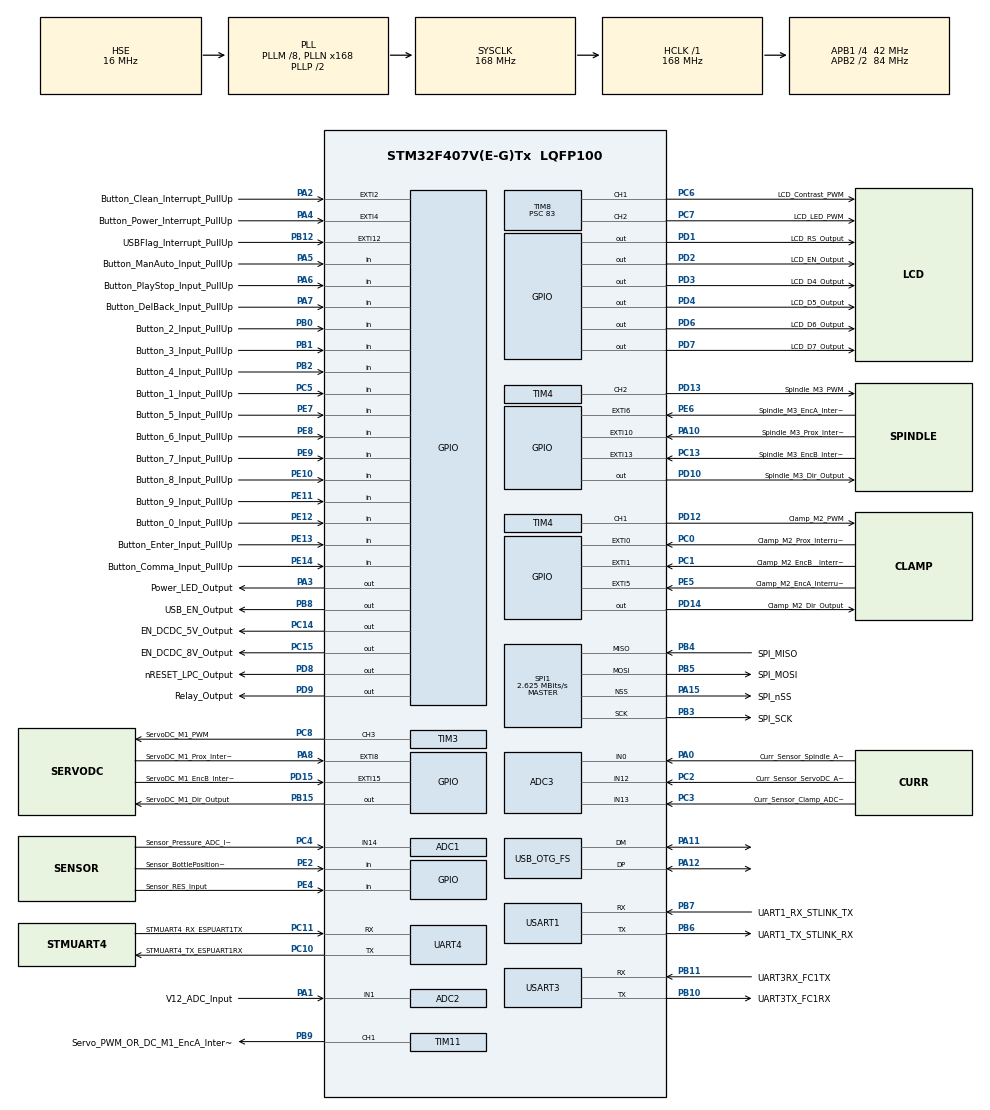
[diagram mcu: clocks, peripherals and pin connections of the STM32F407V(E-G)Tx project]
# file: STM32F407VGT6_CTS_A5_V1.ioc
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ADC1.Channel-0\#ChannelRegularConversion=ADC_CHANNEL_14
ADC1.ClockPrescaler=ADC_CLOCK_SYNC_PCLK_DIV8
ADC1.NbrOfConversionFlag=1
ADC1.Rank-0\#ChannelRegularConversion=1
ADC1.SamplingTime-0\#ChannelRegularConversion=ADC_SAMPLETIME_3CYCLES
ADC1.master=1
ADC2.Channel-0\#ChannelRegularConversion=ADC_CHANNEL_1
ADC2.ClockPrescaler=ADC_CLOCK_SYNC_PCLK_DIV8
ADC2.NbrOfConversionFlag=1
ADC2.Rank-0\#ChannelRegularConversion=1
ADC2.SamplingTime-0\#ChannelRegularConversion=ADC_SAMPLETIME_3CYCLES
ADC3.Channel-0\#ChannelRegularConversion=ADC_CHANNEL_0
ADC3.ClockPrescaler=ADC_CLOCK_SYNC_PCLK_DIV8
ADC3.ContinuousConvMode=ENABLE
ADC3.NbrOfConversion=1
ADC3.NbrOfConversionFlag=1
ADC3.Rank-0\#ChannelRegularConversion=1
ADC3.SamplingTime-0\#ChannelRegularConversion=ADC_SAMPLETIME_3CYCLES
Dma.Request0=USART3_RX
Dma.Request1=USART3_TX
Dma.Request2=USART1_RX
Dma.USART1_RX.2.Direction=DMA_PERIPH_TO_MEMORY
Dma.USART1_RX.2.FIFOMode=DMA_FIFOMODE_DISABLE
Dma.USART1_RX.2.Instance=DMA2_Stream2
Dma.USART1_RX.2.MemDataAlignment=DMA_MDATAALIGN_BYTE
Dma.USART1_RX.2.MemInc=DMA_MINC_ENABLE
Dma.USART1_RX.2.Mode=DMA_NORMAL
Dma.USART1_RX.2.PeriphDataAlignment=DMA_PDATAALIGN_BYTE
Dma.USART1_RX.2.PeriphInc=DMA_PINC_DISABLE
Dma.USART1_RX.2.Priority=DMA_PRIORITY_LOW
Dma.USART3_RX.0.Direction=DMA_PERIPH_TO_MEMORY
Dma.USART3_RX.0.FIFOMode=DMA_FIFOMODE_DISABLE
Dma.USART3_RX.0.Instance=DMA1_Stream1
Dma.USART3_RX.0.MemDataAlignment=DMA_MDATAALIGN_BYTE
Dma.USART3_RX.0.MemInc=DMA_MINC_ENABLE
Dma.USART3_RX.0.Mode=DMA_NORMAL
Dma.USART3_RX.0.PeriphDataAlignment=DMA_PDATAALIGN_BYTE
Dma.USART3_RX.0.PeriphInc=DMA_PINC_DISABLE
Dma.USART3_RX.0.Priority=DMA_PRIORITY_LOW
Dma.USART3_TX.1.Direction=DMA_MEMORY_TO_PERIPH
Dma.USART3_TX.1.FIFOMode=DMA_FIFOMODE_DISABLE
Dma.USART3_TX.1.Instance=DMA1_Stream3
Dma.USART3_TX.1.MemDataAlignment=DMA_MDATAALIGN_BYTE
Dma.USART3_TX.1.MemInc=DMA_MINC_ENABLE
Dma.USART3_TX.1.Mode=DMA_NORMAL
Dma.USART3_TX.1.PeriphDataAlignment=DMA_PDATAALIGN_BYTE
Dma.USART3_TX.1.PeriphInc=DMA_PINC_DISABLE
Dma.USART3_TX.1.Priority=DMA_PRIORITY_LOW
FATFS._MAX_SS=4096
FATFS._USE_LFN=1
FREERTOS.Tasks01=defaultTask,0,128,StartDefaultTask,Default,NULL,Dynamic,NULL,NULL
Mcu.Family=STM32F4
Mcu.Name=STM32F407V(E-G)Tx
Mcu.Package=LQFP100
NVIC.DMA1_Stream1_IRQn=true\:5\:0\:false\:false\:true\:true\:false\:true\:true
NVIC.DMA1_Stream3_IRQn=true\:5\:0\:false\:false\:true\:true\:false\:true\:true
NVIC.DMA2_Stream2_IRQn=true\:5\:0\:false\:false\:true\:true\:false\:true\:true
NVIC.EXTI0_IRQn=true\:5\:0\:false\:true\:true\:8\:true\:true\:true\:true
NVIC.EXTI15_10_IRQn=true\:5\:0\:false\:true\:true\:2\:true\:true\:true\:true
NVIC.EXTI1_IRQn=true\:5\:0\:false\:true\:true\:7\:true\:true\:true\:true
NVIC.EXTI2_IRQn=true\:5\:0\:false\:true\:true\:6\:true\:true\:true\:true
NVIC.EXTI4_IRQn=true\:5\:0\:false\:true\:true\:5\:true\:true\:true\:true
NVIC.EXTI9_5_IRQn=true\:5\:0\:false\:true\:true\:4\:true\:true\:true\:true
NVIC.FLASH_IRQn=true\:5\:0\:false\:false\:true\:true\:true\:true\:true
NVIC.PVD_IRQn=true\:5\:0\:false\:true\:true\:9\:true\:true\:true\:true
NVIC.PriorityGroup=NVIC_PRIORITYGROUP_4
NVIC.RCC_IRQn=true\:5\:0\:false\:false\:true\:true\:true\:false\:true
NVIC.TIM1_UP_TIM10_IRQn=true\:15\:0\:false\:false\:true\:false\:true\:true\:true
NVIC.TIM2_IRQn=true\:5\:0\:false\:true\:true\:3\:true\:true\:true\:true
NVIC.TIM6_DAC_IRQn=true\:5\:0\:false\:false\:true\:true\:true\:true\:true
NVIC.TIM7_IRQn=true\:5\:0\:false\:true\:true\:1\:true\:true\:true\:true
NVIC.TIM8_TRG_COM_TIM14_IRQn=true\:5\:0\:false\:false\:true\:true\:true\:true\:true
NVIC.TimeBase=TIM1_UP_TIM10_IRQn
NVIC.TimeBaseIP=TIM1
NVIC.USART1_IRQn=true\:5\:0\:false\:false\:true\:true\:true\:true\:true
NVIC.USART3_IRQn=true\:5\:0\:false\:false\:true\:true\:true\:true\:true
PA0-WKUP.GPIO_Label=Curr_Sensor_Spindle_ADC_Input
PA0-WKUP.Signal=ADCx_IN0
PA1.GPIO_Label=V12_ADC_Input
PA1.Signal=ADCx_IN1
PA10.GPIO_Label=Spindle_M3_Prox_Interrupt
PA10.GPIO_ModeDefaultEXTI=GPIO_MODE_IT_RISING_FALLING
PA10.GPIO_PuPd=GPIO_NOPULL
PA10.Signal=GPXTI10
PA11.Mode=Host_Only
PA11.Signal=USB_OTG_FS_DM
PA12.Mode=Host_Only
PA12.Signal=USB_OTG_FS_DP
PA13.Mode=Serial_Wire
PA13.Signal=SYS_JTMS-SWDIO
PA14.Mode=Serial_Wire
PA14.Signal=SYS_JTCK-SWCLK
PA15.GPIO_Label=SPI_nSS
PA15.Mode=NSS_Signal_Hard_Output
PA15.Signal=SPI1_NSS
PA2.GPIO_Label=Button_Clean_Interrupt_PullUp
PA2.GPIO_ModeDefaultEXTI=GPIO_MODE_IT_FALLING
PA2.GPIO_PuPd=GPIO_PULLUP
PA2.Signal=GPXTI2
PA3.GPIO_Label=Power_LED_Output
PA3.Signal=GPIO_Output
PA4.GPIO_Label=Button_Power_Interrupt_PullUp
PA4.GPIO_ModeDefaultEXTI=GPIO_MODE_IT_FALLING
PA4.GPIO_PuPd=GPIO_PULLUP
PA4.Signal=GPXTI4
PA5.GPIO_Label=Button_ManAuto_Input_PullUp
PA5.GPIO_PuPd=GPIO_PULLUP
PA5.Signal=GPIO_Input
PA6.GPIO_Label=Button_PlayStop_Input_PullUp
PA6.GPIO_PuPd=GPIO_PULLUP
PA6.Signal=GPIO_Input
PA7.GPIO_Label=Button_DelBack_Input_PullUp
PA7.GPIO_PuPd=GPIO_PULLUP
PA7.Signal=GPIO_Input
PA8.GPIO_Label=ServoDC_M1_Prox_Interrupt
PA8.GPIO_ModeDefaultEXTI=GPIO_MODE_IT_RISING_FALLING
PA8.GPIO_PuPd=GPIO_NOPULL
PA8.Signal=GPXTI8
PB0.GPIO_Label=Button_2_Input_PullUp
PB0.GPIO_PuPd=GPIO_PULLUP
PB0.Signal=GPIO_Input
PB1.GPIO_Label=Button_3_Input_PullUp
PB1.GPIO_PuPd=GPIO_PULLUP
PB1.Signal=GPIO_Input
PB10.GPIO_Label=UART3TX_FC1RX
PB10.Mode=Asynchronous
PB10.Signal=USART3_TX
PB11.GPIO_Label=UART3RX_FC1TX
PB11.Mode=Asynchronous
PB11.Signal=USART3_RX
PB12.GPIO_Label=USBFlag_Interrupt_PullUp
PB12.GPIO_ModeDefaultEXTI=GPIO_MODE_IT_FALLING
PB12.GPIO_PuPd=GPIO_PULLUP
PB12.Signal=GPXTI12
PB15.GPIO_Label=ServoDC_M1_Dir_Output
PB15.Signal=GPIO_Output
PB2.GPIO_Label=Button_4_Input_PullUp
PB2.GPIO_PuPd=GPIO_PULLUP
PB2.Signal=GPIO_Input
PB3.GPIO_Label=SPI_SCK
PB3.Mode=Full_Duplex_Master
PB3.Signal=SPI1_SCK
PB4.GPIO_Label=SPI_MISO
PB4.Mode=Full_Duplex_Master
PB4.Signal=SPI1_MISO
PB5.GPIO_Label=SPI_MOSI
PB5.Mode=Full_Duplex_Master
PB5.Signal=SPI1_MOSI
PB6.GPIO_Label=UART1_TX_STLINK_RX
PB6.Mode=Asynchronous
PB6.Signal=USART1_TX
PB7.GPIO_Label=UART1_RX_STLINK_TX
PB7.Mode=Asynchronous
PB7.Signal=USART1_RX
PB8.GPIO_Label=USB_EN_Output
PB8.Signal=GPIO_Output
PB9.GPIO_Label=Servo_PWM_OR_DC_M1_EncA_Interrupt
PB9.Signal=S_TIM11_CH1
PC0.GPIO_Label=Clamp_M2_Prox_Interrupt
PC0.GPIO_ModeDefaultEXTI=GPIO_MODE_IT_RISING_FALLING
PC0.GPIO_PuPd=GPIO_NOPULL
PC0.Signal=GPXTI0
PC1.GPIO_Label=Clamp_M2_EncB__Interrupt
PC1.GPIO_ModeDefaultEXTI=GPIO_MODE_IT_FALLING
PC1.GPIO_PuPd=GPIO_NOPULL
PC1.Signal=GPXTI1
PC10.GPIO_Label=STMUART4_TX_ESPUART1RX
PC10.Mode=Asynchronous
PC10.Signal=UART4_TX
PC11.GPIO_Label=STMUART4_RX_ESPUART1TX
PC11.Mode=Asynchronous
PC11.Signal=UART4_RX
PC13-ANTI_TAMP.GPIO_Label=Spindle_M3_EncB_Interrupt
PC13-ANTI_TAMP.GPIO_ModeDefaultEXTI=GPIO_MODE_IT_FALLING
PC13-ANTI_TAMP.GPIO_PuPd=GPIO_NOPULL
PC13-ANTI_TAMP.Signal=GPXTI13
PC14-OSC32_IN.GPIO_Label=EN_DCDC_5V_Output
PC14-OSC32_IN.Signal=GPIO_Output
PC15-OSC32_OUT.GPIO_Label=EN_DCDC_8V_Output
PC15-OSC32_OUT.Signal=GPIO_Output
PC2.GPIO_Label=Curr_Sensor_ServoDC_ADC_Input
PC2.Signal=ADCx_IN12
PC3.GPIO_Label=Curr_Sensor_Clamp_ADC_Input
PC3.Signal=ADCx_IN13
PC4.GPIO_Label=Sensor_Pressure_ADC_Input
PC4.Signal=ADCx_IN14
PC5.GPIO_Label=Button_1_Input_PullUp
PC5.GPIO_PuPd=GPIO_PULLUP
PC5.Signal=GPIO_Input
PC6.GPIO_Label=LCD_Contrast_PWM
PC6.Signal=S_TIM8_CH1
PC7.GPIO_Label=LCD_LED_PWM
PC7.Signal=S_TIM8_CH2
PC8.GPIO_Label=ServoDC_M1_PWM
PC8.Signal=S_TIM3_CH3
PD1.GPIO_Label=LCD_RS_Output
PD1.Signal=GPIO_Output
PD10.GPIO_Label=Spindle_M3_Dir_Output
PD10.Signal=GPIO_Output
PD12.GPIO_Label=Clamp_M2_PWM
PD12.Signal=S_TIM4_CH1
PD13.GPIO_Label=Spindle_M3_PWM
PD13.Signal=S_TIM4_CH2
PD14.GPIO_Label=Clamp_M2_Dir_Output
PD14.Signal=GPIO_Output
PD15.GPIO_Label=ServoDC_M1_EncB_Interrupt
PD15.GPIO_ModeDefaultEXTI=GPIO_MODE_IT_FALLING
PD15.GPIO_PuPd=GPIO_NOPULL
PD15.Signal=GPXTI15
PD2.GPIO_Label=LCD_EN_Output
PD2.Signal=GPIO_Output
PD3.GPIO_Label=LCD_D4_Output
PD3.Signal=GPIO_Output
PD4.GPIO_Label=LCD_D5_Output
PD4.Signal=GPIO_Output
PD6.GPIO_Label=LCD_D6_Output
PD6.Signal=GPIO_Output
PD7.GPIO_Label=LCD_D7_Output
PD7.Signal=GPIO_Output
PD8.GPIO_Label=nRESET_LPC_Output
PD8.Signal=GPIO_Output
PD9.GPIO_Label=Relay_Output
PD9.Signal=GPIO_Output
PE10.GPIO_Label=Button_8_Input_PullUp
PE10.GPIO_PuPd=GPIO_PULLUP
PE10.Signal=GPIO_Input
PE11.GPIO_Label=Button_9_Input_PullUp
PE11.GPIO_PuPd=GPIO_PULLUP
PE11.Signal=GPIO_Input
PE12.GPIO_Label=Button_0_Input_PullUp
PE12.GPIO_PuPd=GPIO_PULLUP
PE12.Signal=GPIO_Input
PE13.GPIO_Label=Button_Enter_Input_PullUp
PE13.GPIO_PuPd=GPIO_PULLUP
PE13.Signal=GPIO_Input
PE14.GPIO_Label=Button_Comma_Input_PullUp
PE14.GPIO_PuPd=GPIO_PULLUP
PE14.Signal=GPIO_Input
PE2.GPIO_Label=Sensor_BottlePosition_Input
PE2.Signal=GPIO_Input
PE4.GPIO_Label=Sensor_RES_Input
PE4.Signal=GPIO_Input
PE5.GPIO_Label=Clamp_M2_EncA_Interrupt
PE5.GPIO_ModeDefaultEXTI=GPIO_MODE_IT_FALLING
PE5.GPIO_PuPd=GPIO_NOPULL
PE5.Signal=GPXTI5
PE6.GPIO_Label=Spindle_M3_EncA_Interrupt
PE6.GPIO_ModeDefaultEXTI=GPIO_MODE_IT_FALLING
PE6.GPIO_PuPd=GPIO_NOPULL
PE6.Signal=GPXTI6
PE7.GPIO_Label=Button_5_Input_PullUp
PE7.GPIO_PuPd=GPIO_PULLUP
PE7.Signal=GPIO_Input
PE8.GPIO_Label=Button_6_Input_PullUp
PE8.GPIO_PuPd=GPIO_PULLUP
PE8.Signal=GPIO_Input
PE9.GPIO_Label=Button_7_Input_PullUp
PE9.GPIO_PuPd=GPIO_PULLUP
PE9.Signal=GPIO_Input
PH0-OSC_IN.GPIO_Label=PH0-OSC_IN
PH0-OSC_IN.Mode=HSE-External-Oscillator
PH0-OSC_IN.Signal=RCC_OSC_IN
PH1-OSC_OUT.GPIO_Label=PH1-OSC_OUT
PH1-OSC_OUT.Mode=HSE-External-Oscillator
PH1-OSC_OUT.Signal=RCC_OSC_OUT
ProjectManager.HeapSize=0x200
ProjectManager.StackSize=0x400
ProjectManager.TargetToolchain=STM32CubeIDE
RCC.48MHZClocksFreq_Value=48000000
RCC.AHBFreq_Value=168000000
RCC.APB1CLKDivider=RCC_HCLK_DIV4
RCC.APB1Freq_Value=42000000
RCC.APB1TimFreq_Value=84000000
RCC.APB2CLKDivider=RCC_HCLK_DIV2
RCC.APB2Freq_Value=84000000
RCC.APB2TimFreq_Value=168000000
RCC.CortexFreq_Value=168000000
RCC.HCLKFreq_Value=168000000
RCC.HSE_VALUE=16000000
RCC.HSI_VALUE=16000000
RCC.LSE_VALUE=32768
RCC.PLLM=8
RCC.PLLN=168
RCC.PLLQ=7
RCC.SYSCLKFreq_VALUE=168000000
RCC.SYSCLKSource=RCC_SYSCLKSOURCE_PLLCLK
RCC.VCOOutputFreq_Value=336000000
SH.ADCx_IN0.0=ADC3_IN0,IN0
SH.ADCx_IN1.0=ADC2_IN1,IN1
SH.ADCx_IN12.0=ADC3_IN12,IN12
SH.ADCx_IN13.0=ADC3_IN13,IN13
SH.ADCx_IN14.0=ADC1_IN14,IN14
SH.S_TIM11_CH1.0=TIM11_CH1,PWM Generation1 CH1
SH.S_TIM3_CH3.0=TIM3_CH3,PWM Generation3 CH3
SH.S_TIM4_CH1.0=TIM4_CH1,PWM Generation1 CH1
SH.S_TIM4_CH2.0=TIM4_CH2,PWM Generation2 CH2
SH.S_TIM8_CH1.0=TIM8_CH1,PWM Generation1 CH1
SH.S_TIM8_CH2.0=TIM8_CH2,PWM Generation2 CH2
SPI1.BaudRatePrescaler=SPI_BAUDRATEPRESCALER_32
SPI1.CalculateBaudRate=2.625 MBits/s
SPI1.Direction=SPI_DIRECTION_2LINES
SPI1.Mode=SPI_MODE_MASTER
SPI1.VirtualNSS=VM_NSSHARD
SPI1.VirtualType=VM_MASTER
TIM10.Period=270
TIM10.Prescaler=65535
TIM11.Channel=TIM_CHANNEL_1
TIM11.Period=3029
TIM11.Prescaler=509
TIM2.Period=4999
TIM2.Prescaler=16799
TIM3.Channel-PWM\ Generation3\ CH3=TIM_CHANNEL_3
TIM3.Period=499
TIM3.Prescaler=83
TIM4.Channel-PWM\ Generation1\ CH1=TIM_CHANNEL_1
TIM4.Channel-PWM\ Generation2\ CH2=TIM_CHANNEL_2
TIM4.Period=499
TIM4.Prescaler=83
TIM6.Period=19999
TIM6.Prescaler=8399
TIM7.Period=999
TIM7.Prescaler=8399
TIM8.Channel-PWM\ Generation1\ CH1=TIM_CHANNEL_1
TIM8.Channel-PWM\ Generation2\ CH2=TIM_CHANNEL_2
TIM8.Period=499
TIM8.Prescaler=83
UART4.VirtualMode=Asynchronous
USART1.VirtualMode=VM_ASYNC
USART3.VirtualMode=VM_ASYNC
USB_OTG_FS.VirtualMode=Host_Only
USB_OTG_FS.phy_itface=HCD_PHY_EMBEDDED
VP_FATFS_VS_Generic.Mode=User_defined
VP_FREERTOS_VS_CMSIS_V1.Mode=CMSIS_V1
VP_SYS_VS_tim1.Mode=TIM1
VP_TIM10_VS_ClockSourceINT.Mode=Enable_Timer
VP_TIM11_VS_ClockSourceINT.Mode=Enable_Timer
VP_TIM2_VS_ClockSourceINT.Mode=Internal
VP_TIM3_VS_ClockSourceINT.Mode=Internal
VP_TIM4_VS_ClockSourceINT.Mode=Internal
VP_TIM6_VS_ClockSourceINT.Mode=Enable_Timer
VP_TIM7_VS_ClockSourceINT.Mode=Enable_Timer
VP_TIM8_VS_ClockSourceINT.Mode=Internal
board=STM32F407G-DISC1

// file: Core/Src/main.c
/* USER CODE BEGIN Header */
/**
  ******************************************************************************
  * @file           : main.c
  * @brief          : Main program body
  ******************************************************************************
  * @attention
  *
  * Copyright (c) 2024 STMicroelectronics.
  * All rights reserved.
  *
  * This software is licensed under terms that can be found in the LICENSE file
  * in the root directory of this software component.
  * If no LICENSE file comes with this software, it is provided AS-IS.
  *
  ******************************************************************************
  */
/* USER CODE END Header */
#include "main.h"
#include "cmsis_os.h"
#include "adc.h"
#include "dma.h"
#include "fatfs.h"
#include "spi.h"
#include "tim.h"
#include "usart.h"
#include "usb_otg.h"
#include "gpio.h"
#include "RTOS.h"
#include "CustomerApp.h"

/* USER CODE BEGIN PD */
#define  MAJOR_VERSION  6

#define  MINOR_VERSION  0
#define  PATCH_VERSION  0
// 6 new Work flow chart implementation
// 5 water valve open for 2s in auto operation, previously 0.5s.
// 4 average filter added but not used, future filter added with RDNUM value 5.
// 3 removed auto Taring from developer Menu
                        // 1  Added Valve open and close before auto dispensing removed auto Taring from developer Menu
/* USER CODE END PD */

void SystemClock_Config(void);
void MX_FREERTOS_Init(void);
static void MX_NVIC_Init(void);

/* USER CODE BEGIN 0 */
extern UART_HandleTypeDef huart3;
extern UART_HandleTypeDef huart1;
//uint8_t txBuffer[5] = "TARE";
uint8_t rxBuffer[8];
extern uint8_t dst[8];
uint8_t rxBuffer1[11];
uint8_t dst1[11];

char VERSION_NO[10];  // Allocate a buffer for the version string
/* USER CODE END 0 */

int main(void)
{

  /* MCU Configuration--------------------------------------------------------*/

  /* Reset of all peripherals, Initializes the Flash interface and the Systick. */
  HAL_Init();

  /* Configure the system clock */
  SystemClock_Config();

  /* Initialize all configured peripherals */
  MX_GPIO_Init();
  MX_DMA_Init();
  MX_ADC1_Init();
  MX_ADC2_Init();
  MX_ADC3_Init();
  MX_SPI1_Init();
  MX_TIM3_Init();
  MX_TIM4_Init();
  MX_TIM8_Init();
  MX_TIM11_Init();
  MX_UART4_Init();
  MX_USART1_UART_Init();
  MX_USART3_UART_Init();
  MX_USB_OTG_FS_HCD_Init();
  MX_TIM2_Init();
  MX_TIM7_Init();
  MX_TIM10_Init();
  MX_FATFS_Init();
  MX_TIM6_Init();

  /* Initialize interrupts */
  MX_NVIC_Init();
  /* USER CODE BEGIN 2 */
//  HAL_Delay(3000);
	// Start Timer 7 in interrupt mode
  HAL_TIM_Base_Start_IT(&htim7);
  HAL_TIM_Base_Start_IT(&htim2);
  /** ENABLING LPC  AND THE LOAD CELLS WILL GET ACTIVATED **/
  HAL_GPIO_WritePin(GPIOC, EN_DCDC_5V_Output_Pin|EN_DCDC_8V_Output_Pin, GPIO_PIN_SET);
  //HAL_GPIO_WritePin(GPIOD, nRESET_LPC_Output_Pin, GPIO_PIN_SET);
  /********************************************************/
  HAL_Delay(1000);
  moveMotor(VALVEMOTOR, OFF, INT_INF);
  Servo_Init();
  digitalWrite(Spindle_M3_Dir_Output, LOW);
  digitalWrite(Clamp_M2_Dir_Output, LOW);
  pwm(Spindle_M3_PWM, 0);
  pwm(Clamp_M2_PWM, 0);
  sd_Card_Check();

  if (isMachineOn == FALSE) {
		goToSleep(); // Ensure goToSleep is adapted for STM32
	}

  //HAL_GPIO_WritePin(GPIOC, EN_DCDC_5V_Output_Pin|EN_DCDC_8V_Output_Pin, GPIO_PIN_SET);
  HAL_GPIO_WritePin(GPIOD, nRESET_LPC_Output_Pin, GPIO_PIN_SET);
  //HAL_Delay(1000);
  HAL_TIM_Base_Start_IT(&htim6);
  /* testing in the go sleep for faster response
	  MX_TIM8_Init();
	  LCD_Init();
	  LCDRGBControl(WHITE);
	  controlLCDContrast(100);
  */
  /* THIS iS DEVELOPER AND TESTING PURPOSE ONLE */
  printLCD(0, "SOFTWARE VER ", NO_SYMBOL);
  snprintf(VERSION_NO, sizeof(VERSION_NO), "%d.%d.%d ", MAJOR_VERSION,MINOR_VERSION,PATCH_VERSION);
  printLCD(1, VERSION_NO, NO_SYMBOL);
  /************************************************/

  CTS_Home_position();
//  HAL_Delay(100);
  HAL_UART_Receive_DMA(&huart3, rxBuffer, 8);
  HAL_UART_Receive_DMA(&huart1, rxBuffer1, 11);
  HAL_TIM_Base_Start_IT(&htim10);
  LoadTimeFromSDCard(0,0,0);
  UpdateTimeToSDCard(hours,  minutes,  seconds);

  /* USER CODE END 2 */

  /* Call init function for freertos objects (in freertos.c) */
  MX_FREERTOS_Init();

  /* Start scheduler */
  //osKernelStart();
  LCD_Q = xQueueCreate(5, sizeof(LCDMessage_t));
  xTaskCreate(CustomerFrontEnd, "CustomerTask", 256, NULL, 2, NULL);
  vTaskStartScheduler();
  /* We should never get here as control is now taken by the scheduler */
  /* Infinite loop */
  /* USER CODE BEGIN WHILE */

  while (1)
 {

	/*  if (ProgramToRun == CUSTOMERAPP) {
			CustomerFrontEnd();
		}
	  else if (ProgramToRun == TESTAPP) {
			MotorTest();
	  }
	  else {
			DemoApp();
	  }*/

    /* USER CODE END WHILE */

  }
}

void SystemClock_Config(void)
{
  RCC_OscInitTypeDef RCC_OscInitStruct = {0};
  RCC_ClkInitTypeDef RCC_ClkInitStruct = {0};

  /** Configure the main internal regulator output voltage
  */
  __HAL_RCC_PWR_CLK_ENABLE();
  __HAL_PWR_VOLTAGESCALING_CONFIG(PWR_REGULATOR_VOLTAGE_SCALE1);

  /** Initializes the RCC Oscillators according to the specified parameters
  * in the RCC_OscInitTypeDef structure.
  */
  RCC_OscInitStruct.OscillatorType = RCC_OSCILLATORTYPE_HSE;
  RCC_OscInitStruct.HSEState = RCC_HSE_ON;
  RCC_OscInitStruct.PLL.PLLState = RCC_PLL_ON;
  RCC_OscInitStruct.PLL.PLLSource = RCC_PLLSOURCE_HSE;
  RCC_OscInitStruct.PLL.PLLM = 8;
  RCC_OscInitStruct.PLL.PLLN = 168;
  RCC_OscInitStruct.PLL.PLLP = RCC_PLLP_DIV2;
  RCC_OscInitStruct.PLL.PLLQ = 7;
  if (HAL_RCC_OscConfig(&RCC_OscInitStruct) != HAL_OK)
  {
    Error_Handler();
  }

  /** Initializes the CPU, AHB and APB buses clocks
  */
  RCC_ClkInitStruct.ClockType = RCC_CLOCKTYPE_HCLK|RCC_CLOCKTYPE_SYSCLK
                              |RCC_CLOCKTYPE_PCLK1|RCC_CLOCKTYPE_PCLK2;
  RCC_ClkInitStruct.SYSCLKSource = RCC_SYSCLKSOURCE_PLLCLK;
  RCC_ClkInitStruct.AHBCLKDivider = RCC_SYSCLK_DIV1;
  RCC_ClkInitStruct.APB1CLKDivider = RCC_HCLK_DIV4;
  RCC_ClkInitStruct.APB2CLKDivider = RCC_HCLK_DIV2;

  if (HAL_RCC_ClockConfig(&RCC_ClkInitStruct, FLASH_LATENCY_5) != HAL_OK)
  {
    Error_Handler();
  }
}

/**
  * @brief NVIC Configuration.
  * @retval None
  */
static void MX_NVIC_Init(void)
{
  /* TIM7_IRQn interrupt configuration */
  HAL_NVIC_SetPriority(TIM7_IRQn, 5, 0);
  HAL_NVIC_EnableIRQ(TIM7_IRQn);
  /* EXTI15_10_IRQn interrupt configuration */
  HAL_NVIC_SetPriority(EXTI15_10_IRQn, 5, 0);
  HAL_NVIC_EnableIRQ(EXTI15_10_IRQn);
  /* TIM2_IRQn interrupt configuration */
  HAL_NVIC_SetPriority(TIM2_IRQn, 5, 0);
  HAL_NVIC_EnableIRQ(TIM2_IRQn);
  /* EXTI9_5_IRQn interrupt configuration */
  HAL_NVIC_SetPriority(EXTI9_5_IRQn, 5, 0);
  HAL_NVIC_EnableIRQ(EXTI9_5_IRQn);
  /* EXTI4_IRQn interrupt configuration */
  HAL_NVIC_SetPriority(EXTI4_IRQn, 5, 0);
  HAL_NVIC_EnableIRQ(EXTI4_IRQn);
  /* EXTI2_IRQn interrupt configuration */
  HAL_NVIC_SetPriority(EXTI2_IRQn, 5, 0);
  HAL_NVIC_EnableIRQ(EXTI2_IRQn);
  /* EXTI1_IRQn interrupt configuration */
  HAL_NVIC_SetPriority(EXTI1_IRQn, 5, 0);
  HAL_NVIC_EnableIRQ(EXTI1_IRQn);
  /* EXTI0_IRQn interrupt configuration */
  HAL_NVIC_SetPriority(EXTI0_IRQn, 5, 0);
  HAL_NVIC_EnableIRQ(EXTI0_IRQn);
  /* PVD_IRQn interrupt configuration */
  HAL_NVIC_SetPriority(PVD_IRQn, 5, 0);
  HAL_NVIC_EnableIRQ(PVD_IRQn);
}

/* USER CODE BEGIN 4 */

void HAL_UART_RxCpltCallback(UART_HandleTypeDef *huart)
{
   if (huart->Instance == USART3)
   {
	   memcpy(dst,rxBuffer,sizeof(rxBuffer));
	   ReadLoadCellAVG();
       HAL_UART_Receive_DMA(huart, rxBuffer, 8);
   }

}
/* USER CODE END 4 */

void Error_Handler(void)
{
  __disable_irq();
  while (1)
  {
  }
}
